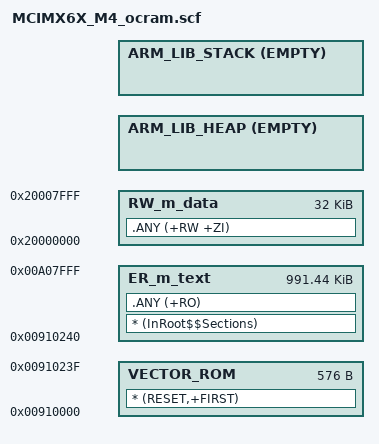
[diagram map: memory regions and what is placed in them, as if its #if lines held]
#! armcc -E
/*
** ###################################################################
**     Processors:          MCIMX6Xxxxx08AB
**                          MCIMX6Xxxxx10AB
**
**     Compiler:            ARM C/C++ Compiler
**     Reference manual:    IMX6SXRM, Rev.A, February 2015
**     Version:             rev. 1.0, 2015-07-29
**
**     Abstract:
**         Linker file for the ARM C/C++ Compiler
**
**     Copyright (c) 2015 Freescale Semiconductor, Inc.
**     Copyright 2016 NXP
**     All rights reserved.
**
**     
**     SPDX-License-Identifier: BSD-3-Clause
**
**     http:                 www.freescale.com
**     mail:                 support@freescale.com
**
** ###################################################################
*/

#define m_interrupts_start             0x00910000
#define m_interrupts_size              0x00000240

#define m_text_start                   0x00910240
#define m_text_size                    0x000F7DC0

#define m_data_start                   0x20000000
#define m_data_size                    0x8000

/* Sizes */
#if (defined(__stack_size__))
  #define Stack_Size                   __stack_size__
#else
  #define Stack_Size                   0x0400
#endif

#if (defined(__heap_size__))
  #define Heap_Size                    __heap_size__
#else
  #define Heap_Size                    0x0400
#endif

LR_m_text m_text_start m_text_size {   ; load region size_region
  ER_m_text m_text_start m_text_size { ; load address = execution address
    * (InRoot$$Sections)
    .ANY (+RO)
  }
  RW_m_data m_data_start m_data_size { ; RW data
    .ANY (+RW +ZI)
  }
  ARM_LIB_HEAP m_data_start+m_data_size-Heap_Size-Stack_Size EMPTY  Heap_Size { ; Heap region growing up
  }
  ARM_LIB_STACK m_data_start+m_data_size EMPTY -Stack_Size { ; Stack region growing down
  }
}

LR_m_interrupts m_interrupts_start m_interrupts_size {
  VECTOR_ROM m_interrupts_start m_interrupts_size { ; load address = execution address
    * (RESET,+FIRST)
  }
}
